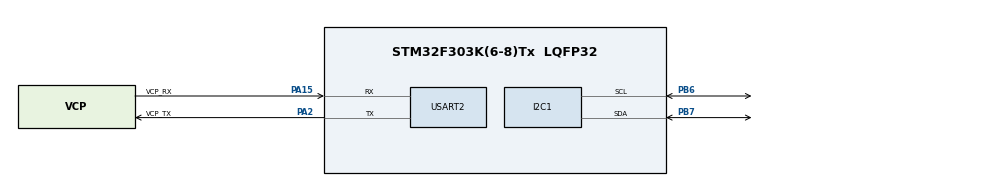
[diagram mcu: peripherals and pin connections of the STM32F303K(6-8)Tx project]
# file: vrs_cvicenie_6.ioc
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Dma.I2C1_TX.1.Direction=DMA_MEMORY_TO_PERIPH
Dma.I2C1_TX.1.Instance=DMA1_Channel2
Dma.I2C1_TX.1.MemDataAlignment=DMA_MDATAALIGN_BYTE
Dma.I2C1_TX.1.MemInc=DMA_MINC_ENABLE
Dma.I2C1_TX.1.Mode=DMA_NORMAL
Dma.I2C1_TX.1.PeriphDataAlignment=DMA_PDATAALIGN_BYTE
Dma.I2C1_TX.1.PeriphInc=DMA_PINC_DISABLE
Dma.I2C1_TX.1.Priority=DMA_PRIORITY_LOW
Dma.Request0=USART2_RX
Dma.Request1=I2C1_TX
Dma.USART2_RX.0.Direction=DMA_PERIPH_TO_MEMORY
Dma.USART2_RX.0.Instance=DMA1_Channel6
Dma.USART2_RX.0.MemDataAlignment=DMA_MDATAALIGN_BYTE
Dma.USART2_RX.0.MemInc=DMA_MINC_ENABLE
Dma.USART2_RX.0.Mode=DMA_NORMAL
Dma.USART2_RX.0.PeriphDataAlignment=DMA_PDATAALIGN_BYTE
Dma.USART2_RX.0.PeriphInc=DMA_PINC_DISABLE
Dma.USART2_RX.0.Priority=DMA_PRIORITY_LOW
Mcu.Family=STM32F3
Mcu.Name=STM32F303K(6-8)Tx
Mcu.Package=LQFP32
NVIC.DMA1_Channel2_IRQn=true\:0\:0\:false\:false\:true\:false\:true\:true
NVIC.DMA1_Channel6_IRQn=true\:0\:0\:false\:false\:true\:false\:true\:true
NVIC.I2C1_EV_IRQn=true\:0\:0\:false\:false\:true\:true\:true\:true
NVIC.PriorityGroup=NVIC_PRIORITYGROUP_4
NVIC.USART2_IRQn=true\:0\:0\:false\:false\:true\:true\:true\:true
PA13.GPIO_Label=SWDIO
PA13.Mode=Serial_Wire
PA13.Signal=SYS_JTMS-SWDIO
PA14.GPIO_Label=SWCLK
PA14.Mode=Serial_Wire
PA14.Signal=SYS_JTCK-SWCLK
PA15.GPIO_Label=VCP_RX
PA15.Mode=Asynchronous
PA15.Signal=USART2_RX
PA2.GPIO_Label=VCP_TX
PA2.Mode=Asynchronous
PA2.Signal=USART2_TX
PB6.Mode=I2C
PB6.Signal=I2C1_SCL
PB7.Mode=I2C
PB7.Signal=I2C1_SDA
PF0\ /\ OSC_IN.GPIO_Label=MCO
PF0\ /\ OSC_IN.Mode=HSE-External-Clock-Source
PF0\ /\ OSC_IN.Signal=RCC_OSC_IN
ProjectManager.HeapSize=0x200
ProjectManager.StackSize=0x400
ProjectManager.TargetToolchain=STM32CubeIDE
RCC.AHBFreq_Value=8000000
RCC.APB1Freq_Value=8000000
RCC.APB2Freq_Value=8000000
RCC.CortexFreq_Value=8000000
RCC.HSE_VALUE=8000000
RCC.HSI_VALUE=8000000
RCC.SYSCLKFreq_VALUE=8000000
USART2.VirtualMode-Asynchronous=VM_ASYNC
board=NUCLEO-F303K8

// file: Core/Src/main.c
/* USER CODE BEGIN Header */
/**
  ******************************************************************************
  * @file           : main.c
  * @brief          : Main program body
  ******************************************************************************
  * @attention
  *
  * Copyright (c) 2023 STMicroelectronics.
  * All rights reserved.
  *
  * This software is licensed under terms that can be found in the LICENSE file
  * in the root directory of this software component.
  * If no LICENSE file comes with this software, it is provided AS-IS.
  *
  ******************************************************************************
  */
/* USER CODE END Header */
#include "main.h"
#include "dma.h"
#include "i2c.h"
#include "usart.h"
#include "gpio.h"

#include "string.h"
#include "stdio.h"
#include "stm32f3xx_it.h"

#include "../Drivers/LPS25HB/lps25hb.h"
#include "../Drivers/HTS221/hts221.h"
#include "../Drivers/tlv493c/tlv493.h"

void SystemClock_Config(void);

int main(void)
{

  /* MCU Configuration--------------------------------------------------------*/

  /* Reset of all peripherals, Initializes the Flash interface and the Systick. */
  HAL_Init();

  /* Configure the system clock */
  SystemClock_Config();

  /* Initialize all configured peripherals */
  MX_GPIO_Init();
  MX_DMA_Init();
  MX_USART2_UART_Init();
  MX_I2C1_Init();

  /* Infinite loop */
  /* USER CODE BEGIN WHILE */
  uint8_t press_sensor_ok =0, temp_sensor_ok=0;
//  uint8_t press_sensor_ok = 0;
//  temp_sensor_ok = hts221_init();
  press_sensor_ok = lps25hb_init();

//  uint8_t *str;
//  int len;
//  float temp = 0, hum = 0, press = 0, alt = 0;
//  str = malloc(32*sizeof(uint8_t));
  uint8_t *str;
  int len;
  float data[3];
  while (1)
  {
    /* USER CODE END WHILE */

//        if(temp_sensor_ok)
//        {
//          temp = hts221_get_temperature();
//          hum = hts221_get_humidity();
//        }
        if(press_sensor_ok)
        {
//          tlv493_test();
           lps25hb_get_pressure(&data);
          LL_mDelay(50);
//          alt = lps25hb_calculate_altitude(press);
        }

		 str = malloc(64*sizeof(uint8_t));
		 len = sprintf(str, "%f,%f,%f\n", data[0],data[1],data[2]);
		 USART2_PutBuffer(str,len);
		 free(str);
//        if(temp > 99.9) temp = 99.9;
//        if(temp < -99.9) temp = -99.9;
//        if(hum > 99) hum = 99;
//        if(hum < 0) hum = 0;
//        if(press > 9999.99) press = 9999.99;
//        if(press < -9999.99) press = -9999.99;
//
//        len = sprintf(str, "%2.1f,%2.0f,%4.2f,%3.2f\n", temp,hum,press,alt);
//        USART2_PutBuffer(str,len);
//        free(str);
  }
}

void SystemClock_Config(void)
{
  LL_FLASH_SetLatency(LL_FLASH_LATENCY_0);
  while(LL_FLASH_GetLatency()!= LL_FLASH_LATENCY_0)
  {
  }
  LL_RCC_HSI_Enable();

   /* Wait till HSI is ready */
  while(LL_RCC_HSI_IsReady() != 1)
  {

  }
  LL_RCC_HSI_SetCalibTrimming(16);
  LL_RCC_SetAHBPrescaler(LL_RCC_SYSCLK_DIV_1);
  LL_RCC_SetAPB1Prescaler(LL_RCC_APB1_DIV_1);
  LL_RCC_SetAPB2Prescaler(LL_RCC_APB2_DIV_1);
  LL_RCC_SetSysClkSource(LL_RCC_SYS_CLKSOURCE_HSI);

   /* Wait till System clock is ready */
  while(LL_RCC_GetSysClkSource() != LL_RCC_SYS_CLKSOURCE_STATUS_HSI)
  {

  }
  LL_SetSystemCoreClock(8000000);

   /* Update the time base */
  if (HAL_InitTick (TICK_INT_PRIORITY) != HAL_OK)
  {
    Error_Handler();
  }
  LL_RCC_SetI2CClockSource(LL_RCC_I2C1_CLKSOURCE_HSI);
}

void Error_Handler(void)
{
  __disable_irq();
  while (1)
  {
  }
}
